# pse84_a0 register map
Vendor: Infineon Technologies; Series: PSE84_A0; File version: 1.0
CPU: CM33 r0p1, little endian, MPU, FPU, VTOR, 3 interrupt priority bits
Registers are 32-bit, read-write, reset 0x0 unless marked. A register's access mark holds for its fields unless they carry their own. Offsets are from the block's base; [hi:lo] are bit positions; lines under a group give offsets from that group; {n}, {i} and the like mark numbered series; 'fields as' and 'values as' point back to an identical list; <NAME> marks a mode.

## USBHS (part 4 of 7) — Regmap for both Subsystem and Controller IP
Base 0x44900000
0x00 DWC_OTG_INTREG group — Internal register map
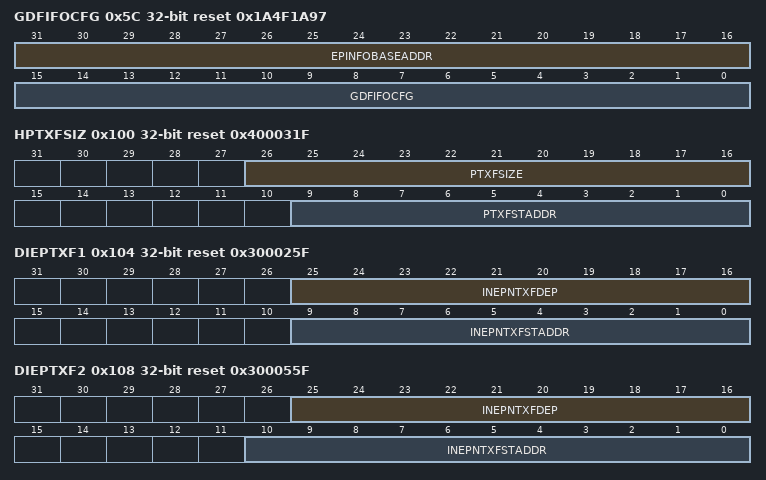
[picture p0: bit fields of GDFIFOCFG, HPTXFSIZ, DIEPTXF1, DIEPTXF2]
  0x5C GDFIFOCFG reset 0x1A4F1A97 — Register to configure the DFIFOs for the controller.
    [31:16] EPINFOBASEADDR — EPInfoBaseAddr This field provides the start address of the EP info controller.
    [15:0] GDFIFOCFG — GDFIFOCfg This field is for dynamic programming of the DFIFO Size. This value takes effect only when the application programs a non zero value to this register. The value programmed must conform to the guidelines described in 'FIFO RAM Allocation'. The core does not have any corrective logic if the FIFO sizes are programmed incorrectly.
  0x68 GINTMSK2 — This register works with the Interrupt Register (GINTSTS2) to interrupt the application. When an interrupt bit is masked, the interrupt associated with that bit is not generated. However, the GINTSTS2 register bit corresponding to that interrupt is still set. Note: The fields of this register change depending on host or device mode.
  0x6C GINTSTS2 — This register interrupts the application for system-level events in the current mode (Device mode or Host mode). Some of the bits in this register are valid only in Host mode, while others are valid in Device mode only. This register also indicates the current mode. To clear the interrupt status bits of type R_SS_WC, the application must write 1'b1 to the bit. The application must clear the GINTSTS2 register at initialization before unmasking the interrupt bit to avoid any interrupts generated prior to initialization.
  0x100 HPTXFSIZ reset 0x400031F — This register holds the size and the memory start address of the Periodic TxFIFO. Note: Read the reset value of this register only after the following conditions: - If IDDIG_FILTER is disabled, read only after PHY clock is stable. - If IDDIG_FILTER is enabled, read only after the filter timer expires.
    [26:16] PTXFSIZE — Host Periodic TxFIFO Depth (PTxFSize) This value is in terms of 32-bit words. - Minimum value is 16 - Maximum value is 32,768 The power-on reset value of this register is specified as the Largest Host Mode Periodic Tx Data FIFO Depth. - If Enable Dynamic FIFO Sizing? was deselected in coreConsultant (parameter OTG_DFIFO_DYNAMIC = 0), these flops are optimized, and reads return the power-on value. - If Enable Dynamic FIFO Sizing? was selected in coreConsultant (parameter OTG_DFIFO_DYNAMIC = 1), you can write a new value in this field. Programmed values must not exceed the power-on value set in coreConsultant.
    [9:0] PTXFSTADDR — Host Periodic TxFIFO Start Address (PTxFStAddr) The power-on reset value of this register is the sum of the Largest Rx Data FIFO Depth and Largest Non-periodic Tx Data FIFO Depth.These parameters are: In shared FIFO operation: - OTG_RX_DFIFO_DEPTH + OTG_TX_NPERIO_DFIFO_DEPTH In dedicated FIFO mode: - OTG_RX_DFIFO_DEPTH + OTG_TX_HNPERIO_DFIFO_DEPTH If Enable Dynamic FIFO Sizing? was deselected in coreConsultant (parameter OTG_DFIFO_DYNAMIC = 0), these flops are optimized, and reads return the power-on value. If Enable Dynamic FIFO Sizing? was selected in coreConsultant (parameter OTG_DFIFO_DYNAMIC = 1), you can write a new value in this field. Programmed values must not exceed the power-on value set in coreConsultant.
  0x104 DIEPTXF1 reset 0x300025F — This register is valid only in dedicated FIFO mode (OTG_EN_DED_TX_FIFO=1). It holds the size and memory start address of IN endpoint TxFIFOs implemented in Device mode. Each FIFO holds the data for one IN endpoint. This register is repeated for instantiated IN endpoint FIFOs 1 to 15. For IN endpoint FIFO 0, use GNPTXFSIZ register for programming the size and memory start address.
    [25:16] INEPNTXFDEP — IN Endpoint TxFIFO Depth (INEPnTxFDep) This value is in terms of 32-bit words. - Minimum value is 16 - Maximum value is 32,768 The power-on reset value of this register is specified as the Largest IN Endpoint FIFO number Depth (parameter OTG_TX_DINEP_DFIFO_DEPTH_n) during coreConsultant configuration (0 < i <= 15). - If 'Enable Dynamic FIFO Sizing?' was deselected in coreConsultant (parameter OTG_DFIFO_DYNAMIC = 0), these flops are optimized, and reads return the power-on value. - If 'Enable Dynamic FIFO Sizing?' was selected in coreConsultant (parameter OTG_DFIFO_DYNAMIC = 1), you can write a new value in this field. Programmed values must not exceed the power-on value.
    [9:0] INEPNTXFSTADDR — IN Endpoint FIFOn Transmit RAM Start Address (INEPnTxFStAddr) This field contains the memory start address for IN endpoint Transmit FIFOn (0<n< = 15). The power-on reset value of this register is specified as the Largest Rx Data FIFO Depth. The power-on reset value of this register is calculated according to the following formula: OTG_RX_DFIFO_DEPTH + SUM of OTG_TX_DINEP_DFIFO_DEPTH_'i' (where x = 0 to n 1) If at POR the calculated value (C) exceeds 65535, then the Reset value becomes Reset Value(A) = (C 65536). Example: If start address of IN endpoint FIFO 1 is OTG_RX_DFIFO_DEPTH + OTG_TX_DINEP_DFIFO_DEPTH_ 0 and start address of IN endpoint FIFO 2 is OTG_RX_DFIFO_DEPTH + OTG_TX_DINEP_DFIFO_DEPTH_ 0 + OTG_TX_DINEP_DFIFO_DEPTH_ 1. - If Enable Dynamic FIFO Sizing is deselected in coreConsultant (OTG_DFIFO_DYNAMIC = 0), this field is read-only and read value is the power-on reset value. - If Enable Dynamic FIFO Sizing is selected in coreConsultant (OTG_DFIFO_DYNAMIC = 1), and you have calculated or programmed a new value for RxFIFO depth or TX FIFO depths, you can program their values according to the above formula. Programmed values must not exceed the power-on value set in coreConsultant.
  0x108 DIEPTXF2 reset 0x300055F — This register is valid only in dedicated FIFO mode (OTG_EN_DED_TX_FIFO=1). It holds the size and memory start address of IN endpoint TxFIFOs implemented in Device mode. Each FIFO holds the data for one IN endpoint. This register is repeated for instantiated IN endpoint FIFOs 1 to 15. For IN endpoint FIFO 0, use GNPTXFSIZ register for programming the size and memory start address.
    [25:16] INEPNTXFDEP — IN Endpoint TxFIFO Depth (INEPnTxFDep) This value is in terms of 32-bit words. - Minimum value is 16 - Maximum value is 32,768 The power-on reset value of this register is specified as the Largest IN Endpoint FIFO number Depth (parameter OTG_TX_DINEP_DFIFO_DEPTH_n) during coreConsultant configuration (0 < i <= 15). - If 'Enable Dynamic FIFO Sizing?' was deselected in coreConsultant (parameter OTG_DFIFO_DYNAMIC = 0), these flops are optimized, and reads return the power-on value. - If 'Enable Dynamic FIFO Sizing?' was selected in coreConsultant (parameter OTG_DFIFO_DYNAMIC = 1), you can write a new value in this field. Programmed values must not exceed the power-on value.
    [10:0] INEPNTXFSTADDR — IN Endpoint FIFOn Transmit RAM Start Address (INEPnTxFStAddr) This field contains the memory start address for IN endpoint Transmit FIFOn (0<n< = 15). The power-on reset value of this register is specified as the Largest Rx Data FIFO Depth. The power-on reset value of this register is calculated according to the following formula: OTG_RX_DFIFO_DEPTH + SUM of OTG_TX_DINEP_DFIFO_DEPTH_'i' (where x = 0 to n 1) If at POR the calculated value (C) exceeds 65535, then the Reset value becomes Reset Value(A) = (C 65536). Example: If start address of IN endpoint FIFO 1 is OTG_RX_DFIFO_DEPTH + OTG_TX_DINEP_DFIFO_DEPTH_ 0 and start address of IN endpoint FIFO 2 is OTG_RX_DFIFO_DEPTH + OTG_TX_DINEP_DFIFO_DEPTH_ 0 + OTG_TX_DINEP_DFIFO_DEPTH_ 1. - If Enable Dynamic FIFO Sizing is deselected in coreConsultant (OTG_DFIFO_DYNAMIC = 0), this field is read-only and read value is the power-on reset value. - If Enable Dynamic FIFO Sizing is selected in coreConsultant (OTG_DFIFO_DYNAMIC = 1), and you have calculated or programmed a new value for RxFIFO depth or TX FIFO depths, you can program their values according to the above formula. Programmed values must not exceed the power-on value set in coreConsultant.
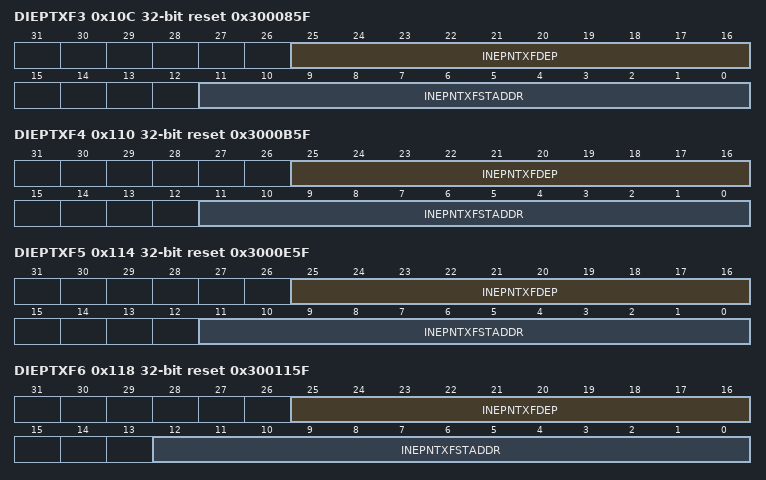
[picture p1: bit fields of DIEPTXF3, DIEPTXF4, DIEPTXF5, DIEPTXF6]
  0x10C DIEPTXF3 reset 0x300085F — This register is valid only in dedicated FIFO mode (OTG_EN_DED_TX_FIFO=1). It holds the size and memory start address of IN endpoint TxFIFOs implemented in Device mode. Each FIFO holds the data for one IN endpoint. This register is repeated for instantiated IN endpoint FIFOs 1 to 15. For IN endpoint FIFO 0, use GNPTXFSIZ register for programming the size and memory start address.
    [25:16] INEPNTXFDEP — IN Endpoint TxFIFO Depth (INEPnTxFDep) This value is in terms of 32-bit words. - Minimum value is 16 - Maximum value is 32,768 The power-on reset value of this register is specified as the Largest IN Endpoint FIFO number Depth (parameter OTG_TX_DINEP_DFIFO_DEPTH_n) during coreConsultant configuration (0 < i <= 15). - If 'Enable Dynamic FIFO Sizing?' was deselected in coreConsultant (parameter OTG_DFIFO_DYNAMIC = 0), these flops are optimized, and reads return the power-on value. - If 'Enable Dynamic FIFO Sizing?' was selected in coreConsultant (parameter OTG_DFIFO_DYNAMIC = 1), you can write a new value in this field. Programmed values must not exceed the power-on value.
    [11:0] INEPNTXFSTADDR — IN Endpoint FIFOn Transmit RAM Start Address (INEPnTxFStAddr) This field contains the memory start address for IN endpoint Transmit FIFOn (0<n< = 15). The power-on reset value of this register is specified as the Largest Rx Data FIFO Depth. The power-on reset value of this register is calculated according to the following formula: OTG_RX_DFIFO_DEPTH + SUM of OTG_TX_DINEP_DFIFO_DEPTH_'i' (where x = 0 to n 1) If at POR the calculated value (C) exceeds 65535, then the Reset value becomes Reset Value(A) = (C 65536). Example: If start address of IN endpoint FIFO 1 is OTG_RX_DFIFO_DEPTH + OTG_TX_DINEP_DFIFO_DEPTH_ 0 and start address of IN endpoint FIFO 2 is OTG_RX_DFIFO_DEPTH + OTG_TX_DINEP_DFIFO_DEPTH_ 0 + OTG_TX_DINEP_DFIFO_DEPTH_ 1. - If Enable Dynamic FIFO Sizing is deselected in coreConsultant (OTG_DFIFO_DYNAMIC = 0), this field is read-only and read value is the power-on reset value. - If Enable Dynamic FIFO Sizing is selected in coreConsultant (OTG_DFIFO_DYNAMIC = 1), and you have calculated or programmed a new value for RxFIFO depth or TX FIFO depths, you can program their values according to the above formula. Programmed values must not exceed the power-on value set in coreConsultant.
  0x110 DIEPTXF4 reset 0x3000B5F — This register is valid only in dedicated FIFO mode (OTG_EN_DED_TX_FIFO=1). It holds the size and memory start address of IN endpoint TxFIFOs implemented in Device mode. Each FIFO holds the data for one IN endpoint. This register is repeated for instantiated IN endpoint FIFOs 1 to 15. For IN endpoint FIFO 0, use GNPTXFSIZ register for programming the size and memory start address.
    fields as DWC_OTG_INTREG.DIEPTXF3
  0x114 DIEPTXF5 reset 0x3000E5F — This register is valid only in dedicated FIFO mode (OTG_EN_DED_TX_FIFO=1). It holds the size and memory start address of IN endpoint TxFIFOs implemented in Device mode. Each FIFO holds the data for one IN endpoint. This register is repeated for instantiated IN endpoint FIFOs 1 to 15. For IN endpoint FIFO 0, use GNPTXFSIZ register for programming the size and memory start address.
    fields as DWC_OTG_INTREG.DIEPTXF3
  0x118 DIEPTXF6 reset 0x300115F — This register is valid only in dedicated FIFO mode (OTG_EN_DED_TX_FIFO=1). It holds the size and memory start address of IN endpoint TxFIFOs implemented in Device mode. Each FIFO holds the data for one IN endpoint. This register is repeated for instantiated IN endpoint FIFOs 1 to 15. For IN endpoint FIFO 0, use GNPTXFSIZ register for programming the size and memory start address.
    [25:16] INEPNTXFDEP — IN Endpoint TxFIFO Depth (INEPnTxFDep) This value is in terms of 32-bit words. - Minimum value is 16 - Maximum value is 32,768 The power-on reset value of this register is specified as the Largest IN Endpoint FIFO number Depth (parameter OTG_TX_DINEP_DFIFO_DEPTH_n) during coreConsultant configuration (0 < i <= 15). - If 'Enable Dynamic FIFO Sizing?' was deselected in coreConsultant (parameter OTG_DFIFO_DYNAMIC = 0), these flops are optimized, and reads return the power-on value. - If 'Enable Dynamic FIFO Sizing?' was selected in coreConsultant (parameter OTG_DFIFO_DYNAMIC = 1), you can write a new value in this field. Programmed values must not exceed the power-on value.
    [12:0] INEPNTXFSTADDR — IN Endpoint FIFOn Transmit RAM Start Address (INEPnTxFStAddr) This field contains the memory start address for IN endpoint Transmit FIFOn (0<n< = 15). The power-on reset value of this register is specified as the Largest Rx Data FIFO Depth. The power-on reset value of this register is calculated according to the following formula: OTG_RX_DFIFO_DEPTH + SUM of OTG_TX_DINEP_DFIFO_DEPTH_'i' (where x = 0 to n 1) If at POR the calculated value (C) exceeds 65535, then the Reset value becomes Reset Value(A) = (C 65536). Example: If start address of IN endpoint FIFO 1 is OTG_RX_DFIFO_DEPTH + OTG_TX_DINEP_DFIFO_DEPTH_ 0 and start address of IN endpoint FIFO 2 is OTG_RX_DFIFO_DEPTH + OTG_TX_DINEP_DFIFO_DEPTH_ 0 + OTG_TX_DINEP_DFIFO_DEPTH_ 1. - If Enable Dynamic FIFO Sizing is deselected in coreConsultant (OTG_DFIFO_DYNAMIC = 0), this field is read-only and read value is the power-on reset value. - If Enable Dynamic FIFO Sizing is selected in coreConsultant (OTG_DFIFO_DYNAMIC = 1), and you have calculated or programmed a new value for RxFIFO depth or TX FIFO depths, you can program their values according to the above formula. Programmed values must not exceed the power-on value set in coreConsultant.
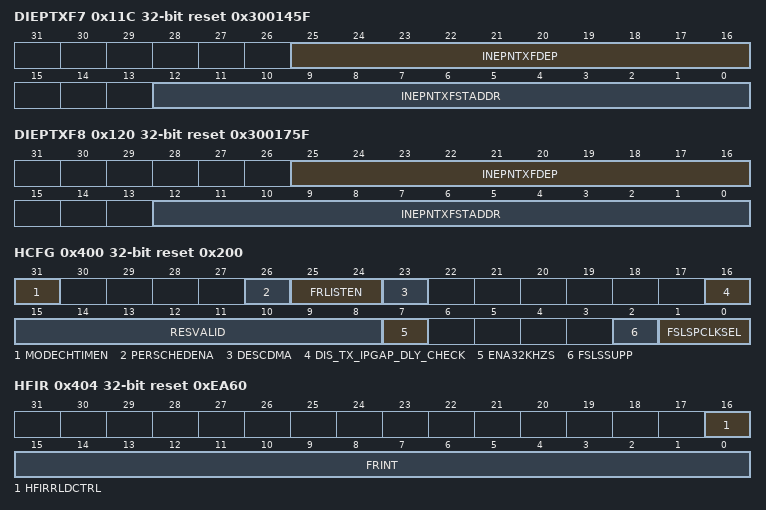
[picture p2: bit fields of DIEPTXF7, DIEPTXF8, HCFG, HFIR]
  0x11C DIEPTXF7 reset 0x300145F — This register is valid only in dedicated FIFO mode (OTG_EN_DED_TX_FIFO=1). It holds the size and memory start address of IN endpoint TxFIFOs implemented in Device mode. Each FIFO holds the data for one IN endpoint. This register is repeated for instantiated IN endpoint FIFOs 1 to 15. For IN endpoint FIFO 0, use GNPTXFSIZ register for programming the size and memory start address.
    fields as DWC_OTG_INTREG.DIEPTXF6
  0x120 DIEPTXF8 reset 0x300175F — This register is valid only in dedicated FIFO mode (OTG_EN_DED_TX_FIFO=1). It holds the size and memory start address of IN endpoint TxFIFOs implemented in Device mode. Each FIFO holds the data for one IN endpoint. This register is repeated for instantiated IN endpoint FIFOs 1 to 15. For IN endpoint FIFO 0, use GNPTXFSIZ register for programming the size and memory start address.
    fields as DWC_OTG_INTREG.DIEPTXF6
  0x400 HCFG reset 0x200 — This register is used to configure the controller in Host mode.
    [31] MODECHTIMEN — Mode Change Ready Timer Enable (ModeChTimEn) This bit is used to enable/disable the Host core to wait 200 PHY clock cycles at the end of Resume to change the opmode signal to the PHY to 00 after Suspend or LPM. - 1'b0 : The Host core waits for either 200 PHY clock cycles or a linestate of SE0 at the end of resume to the change the opmode from 2'b10 to 2'b00 - 1'b1 : The Host core waits only for a linstate of SE0 at the end of resume to change the opmode from 2'b10 to 2'b00.
      1=DISABLED (The Host core waits only for a linestate of SE0 at the end of resume to change the opmode from 0x2 to 0x0); 0=ENABLED (The Host core waits for either 200 PHY clock cycles or a linestate of SE0 at the end of resume to change the opmode from 0x2 to 0x0)
    [26] PERSCHEDENA — Enable Periodic Scheduling (PerSchedEna): Applicable in host DDMA mode only. Enables periodic scheduling within the core. Initially, the bit is reset. The core will not process any periodic channels. As soon as this bit is set, the core will get ready to start scheduling periodic channels and sets HCFG.PerSchedStat. The setting of HCFG.PerSchedStat indicates the core has enabled periodic scheduling. Once HCFG.PerSchedEna is set, the application is not supposed to again reset the bit unless HCFG.PerSchedStat is set. As soon as this bit is reset, the core will get ready to stop scheduling periodic channels and resets HCFG.PerSchedStat.
      0=DISABLED (Disables periodic scheduling within the core); 1=ENABLED (Enables periodic scheduling within the core)
    [25:24] FRLISTEN — Frame List Entries(FrListEn) The value in the register specifies the number of entries in the Frame list. This field is valid only in Scatter/Gather DMA mode. - 2'b00: 8 Entries - 2'b01: 16 Entries - 2'b10: 32 Entries - 2'b11: 64 Entries
      1=ENTRY16 (16 Entries); 2=ENTRY32 (32 Entries); 3=ENTRY63 (64 Entries); 0=ENTRY8 (8 Entries)
    [23] DESCDMA — Enable Scatter/gather DMA in Host mode (DescDMA) When the Scatter/Gather DMA option selected during configuration of the RTL, the application can set this bit during initialization to enable the Scatter/Gather DMA operation. Note: This bit must be modified only once after a reset. The following combinations are available for programming: - GAHBCFG.DMAEn=0,HCFG.DescDMA=0 => Slave mode - GAHBCFG.DMAEn=0,HCFG.DescDMA=1 => Invalid - GAHBCFG.DMAEn=1,HCFG.DescDMA=0 => Buffered DMA mode - GAHBCFG.DMAEn=1,HCFG.DescDMA=1 => Scatter/Gather DMA mode
      0=DISABLED (Scatter/Gather DMA in Host mode is disabled); 1=ENABLED (Scatter/Gather DMA selected)
    [16] DIS_TX_IPGAP_DLY_CHECK — Disable Linestate check for Token to Token/Data interpacket gap delay calculation (dis_tx_ipgap_dly_check) Applicable only in HS mode of operation. When enabled, the controller implements counter based logic to detect the end of token transmission, otherwise controller monitors the linestate for end of token transmission,to start the Token to Token and Token to Data interpacket delay counter.
      0=DISABLE (Enable Linestate check); 1=ENABLE (Disable Linestate check)
    [15:8] RESVALID — Resume Validation Period (ResValid) This field is effective only when HCFG.Ena32KHzS is set. It will control the resume period when the core resumes from suspend. The core counts for 'ResValid' number of clock cycles to detect a valid resume when this is set.
    [7] ENA32KHZS — Enable 32 KHz Suspend mode (Ena32KHzS) This bit can be set only in FS PHY interface is selected. Else, this bit needs to be set to zero. When FS PHY interface is chosen and this bit is set, the core expects that the PHY clock during Suspend is switched from 48 MHz to 32 KHz.
      0=DISABLED (32 KHz Suspend mode disabled); 1=ENABLED (32 KHz Suspend mode enabled)
    [2] FSLSSUPP — FS- and LS-Only Support (FSLSSupp) The application uses this bit to control the core's enumeration speed. Using this bit, the application can make the core enumerate as a FS host, even If the connected device supports HS traffic. Do not make changes to this field after initial programming. - 1'b0: HS/FS/LS, based on the maximum speed supported by the connected device - 1'b1: FS/LS-only, even If the connected device can support HS
      1=FSLS (FS/LS-only, even if the connected device can support HS); 0=HSFSLS (HS/FS/LS, based on the maximum speed supported by the connected device)
    [1:0] FSLSPCLKSEL
      0=CLK3060 (PHY clock is running at 30/60 MHz); 1=CLK48 (PHY clock is running at 48 MHz); 2=CLK6 (PHY clock is running at 6 MHz)
  0x404 HFIR reset 0xEA60 — This register is used to control the interval between two consecutive SOFs.
    [16] HFIRRLDCTRL — Reload Control (HFIRRldCtrl) This bit allows dynamic reloading of the HFIR register during run time. - 1'b0 : The HFIR cannot be reloaded dynamically - 1'b1: the HFIR can be dynamically reloaded during runtime. This bit needs to be programmed during initial configuration and its value should not be changed during runtime.
      0=DISABLED (The HFIR cannot be reloaded dynamically); 1=ENABLED (The HFIR can be dynamically reloaded during runtime)
    [15:0] FRINT — Frame Interval (FrInt) The value that the application programs to this field specifies the interval between two consecutive SOFs (FS) or micro- SOFs (HS) or Keep-Alive tokens (HS). This field contains the number of PHY clocks that constitute the required frame interval. The Default value set in this field is for FS operation when the PHY clock frequency is 60 MHz. The application can write a value to this register only after the Port Enable bit of the Host Port Control and Status register (HPRT.PrtEnaPort) has been Set. If no value is programmed, the core calculates the value based on the PHY clock specified in the FS/LS PHY Clock Select field of the Host Configuration register (HCFG.FSLSPclkSel). Do not change the value of this field after the initial configuration. - 125 s * (PHY clock frequency for HS) - 1 ms * (PHY clock frequency for FS/LS)
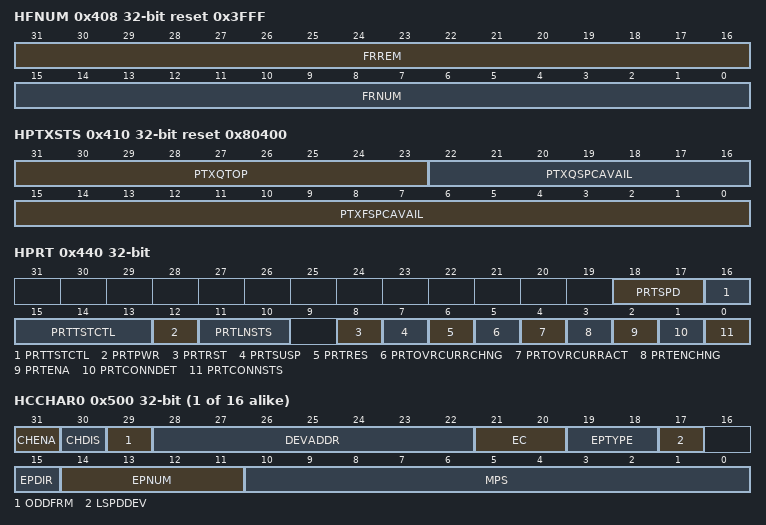
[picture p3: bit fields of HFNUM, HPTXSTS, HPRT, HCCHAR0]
  0x408 HFNUM ro reset 0x3FFF — This register indicates the current frame number. It also indicates the time remaining (in terms of the number of PHY clocks) in the current (micro)frame. Note: Read the reset value of this register only after the following conditions: - If IDDIG_FILTER is disabled, read only when the PHY clock is stable. - If IDDIG_FILTER is enabled, read only after the filter timer expires.
    [31:16] FRREM — Frame Time Remaining (FrRem) Indicates the amount of time remaining in the current microframe (HS) or Frame (FS/LS), in terms of PHY clocks. This field decrements on each PHY clock. When it reaches zero, this field is reloaded with the value in the Frame Interval register and a new SOF is transmitted on the USB.
    [15:0] FRNUM — Frame Number (FrNum) This field increments when a new SOF is transmitted on the USB, and is reset to 0 when it reaches 16'h3FFF.
  0x410 HPTXSTS ro reset 0x80400 — This register contains information about the Periodic Transmit Queue in the Host controller.
    [31:23] PTXQTOP — Top of the Periodic Transmit Request Queue (PTxQTop) This indicates the Entry in the Periodic Tx Request Queue that is currently being processed by the MAC. This register is used for debugging. - Bit [31]: Odd/Even (micro)Frame -- 1'b0: send in even (micro)Frame -- 1'b1: send in odd (micro)Frame - Bits [30:27]: Channel/endpoint number - Bits [26:25]: Type -- 2'b00: IN/OUT -- 2'b01: Zero-length packet -- 2'b10: CSPLIT -- 2'b11: Disable channel command - Bit [24]: Last Periodic Entry for the selected periodic channel/endpoint - Bit [23]: Terminate (last Entry for the selected channel/endpoint)
    [22:16] PTXQSPCAVAIL
    [15:0] PTXFSPCAVAIL
  0x414 HAINT ro — When a significant event occurs on a channel, the Host All Channels Interrupt register interrupts the application using the Host Channels Interrupt bit of the Core Interrupt register (GINTSTS.HChInt). This is shown in the 'Interrupt Hierarchy' figure in the databook. There is one interrupt bit per channel, up to a maximum of 16 bits. Bits in this register are set and cleared when the application sets and clears bits in the corresponding Host Channel-n Interrupt register.
    [15:0] HAINT — Channel Interrupt for channel no.
  0x418 HAINTMSK — The Host All Channel Interrupt Mask register works with the Host All Channel Interrupt register to interrupt the application when an event occurs on a channel. There is one interrupt mask bit per channel, up to a maximum of 16 bits.
    [15:0] HAINTMSK — Channel Interrupt Mask (HAINTMsk) One bit per channel: Bit 0 for channel 0, bit 15 for channel 15
  0x41C HFLBADDR — This register is present only in case of Scatter/Gather DMA. It is implemented as flops. This register holds the starting address of the Frame list information.
    [31:0] HFLBADDR — The starting address of the Frame list. This register is used only for Isochronous and Interrupt Channels.
  0x440 HPRT — This register is available only in Host mode. Currently, the OTG Host supports only one port. A single register holds USB port-related information such as USB reset, enable, suspend, resume, connect status, and test mode for each port. It is shown in the 'Interrupt Hierarchy' figure in the databook. The R_SS_WC bits in this register can trigger an interrupt to the application through the Host Port Interrupt bit of the Core Interrupt register (GINTSTS.PrtInt). On a Port Interrupt, the application must read this register and clear the bit that caused the interrupt. For the R_SS_WC bits, the application must write a 1 to the bit to clear the interrupt.
    [18:17] PRTSPD ro
      1=FULLSPD (Full speed); 0=HIGHSPD (High speed); 2=LOWSPD (Low speed); 3=RSVDPrtSpdHPRT (N/A)
    [16:13] PRTTSTCTL
      0=DISABLED (Test mode disabled); 5=TESTFENB (Test_force_Enable); 1=TESTJ (Test_J mode); 2=TESTK (Test_K mode); 4=TESTPM (Test_Packet mode); 3=TESTSN (Test_SE0_NAK mode)
    [12] PRTPWR — Port Power (PrtPwr) The application uses this field to control power to this port (write 1'b1 to set to 1'b1 and write 1'b0 to set to 1'b0), and the core can clear this bit on an over current condition. - 1'b0: Power off - 1'b1: Power on Note: This bit is interface independent. The application needs to program this bit for all interfaces as described in the host programming flow in the Programming Guide.
      0=OFF (Power off); 1=ON (Power on)
    [11:10] PRTLNSTS ro — Port Line Status (PrtLnSts) Indicates the current logic level USB data lines - Bit [10]: Logic level of D+ - Bit [11]: Logic level of D-
      2=MINUSD (Logic level of D-); 1=PLUSD (Logic level of D+)
    [8] PRTRST — Port Reset (PrtRst) When the application sets this bit, a reset sequence is started on this port. The application must time the reset period and clear this bit after the reset sequence is complete. - 1'b0: Port not in reset - 1'b1: Port in reset The application must leave this bit set for at least a minimum duration mentioned below to start a reset on the port. The application can leave it set for another 10 ms in addition to the required minimum duration, before clearing the bit, even though there is no maximum limit Set by the USB standard.This bit is cleared by the core even if there is no device connected to the Host. - High speed: 50 ms - Full speed/Low speed: 10 ms
      0=DISABLED (Port not in reset); 1=ENABLED (Port in reset)
    [7] PRTSUSP — Port Suspend (PrtSusp) The application sets this bit to put this port in Suspend mode. The core only stops sending SOFs when this is Set. To stop the PHY clock, the application must Set the Port Clock Stop bit, which asserts the suspend input pin of the PHY. The read value of this bit reflects the current suspend status of the port. This bit is cleared by the core after a remote wakeup signal is detected or the application sets the Port Reset bit or Port Resume bit in this register or the Resume/Remote Wakeup Detected Interrupt bit or Disconnect Detected Interrupt bit in the Core Interrupt register (GINTSTS.WkUpInt or GINTSTS.DisconnInt, respectively).This bit is cleared by the core even if there is no device connected to the Host. - 1'b0: Port not in Suspend mode - 1'b1: Port in Suspend mode
      1=ACTIVE (Port in Suspend mode); 0=INACTIVE (Port not in Suspend mode)
    [6] PRTRES — Port Resume (PrtRes) The application sets this bit to drive resume signaling on the port. The core continues to drive the resume signal until the application clears this bit. If the core detects a USB remote wakeup sequence, as indicated by the Port Resume/Remote Wakeup Detected Interrupt bit of the Core Interrupt register (GINTSTS.WkUpInt), the core starts driving resume signaling without application intervention and clears this bit when it detects a disconnect condition. The read value of this bit indicates whether the core is currently driving resume signaling. - 1'b0: No resume driven - 1'b1: Resume driven When LPM is enabled, In L1 state the behavior of this bit is as follows: The application sets this bit to drive resume signaling on the port. The core continues to drive the resume signal until a pre-determined time specified in GLPMCFG.HIRD_Thres[3:0] field. If the core detects a USB remote wakeup sequence, as indicated by the Port L1Resume/Remote L1Wakeup Detected Interrupt bit of the Core Interrupt register (GINTSTS.L1WkUpInt), the core starts driving resume signaling without application intervention and clears this bit at the end of resume.This bit can be set by both core or application and also cleared by core or application. This bit is cleared by the core even if there is no device connected to the Host.
      0=NORESUME (No resume driven); 1=RESUME (Resume driven)
    [5] PRTOVRCURRCHNG — Port Overcurrent Change (PrtOvrCurrChng) The core sets this bit when the status of the Port Overcurrent Active bit (bit 4) in this register changes.This bit can be set only by the core and the application should write 1 to clear it
      1=ACTIVE (Status of port overcurrent changed); 0=INACTIVE (Status of port overcurrent status is not changed)
    [4] PRTOVRCURRACT ro — Port Overcurrent Active (PrtOvrCurrAct) Indicates the overcurrent condition of the port. - 1'b0: No overcurrent condition - 1'b1: Overcurrent condition
      1=ACTIVE (Overcurrent condition); 0=INACTIVE (No overcurrent condition)
    [3] PRTENCHNG — Port Enable/Disable Change (PrtEnChng) The core sets this bit when the status of the Port Enable bit [2] of this register changes.This bit can be set only by the core and the application should write 1 to clear it.
      1=ACTIVE (Port Enable bit 2 changed); 0=INACTIVE (Port Enable bit 2 has not changed)
    [2] PRTENA — Port Enable (PrtEna) A port is enabled only by the core after a reset sequence, and is disabled by an overcurrent condition, a disconnect condition, or by the application clearing this bit. The application cannot Set this bit by a register write. It can only clear it to disable the port by writing 1. This bit does not trigger any interrupt to the application. - 1'b0: Port disabled - 1'b1: Port enabled
      0=DISABLED (Port disabled); 1=ENABLED (Port enabled)
    [1] PRTCONNDET — Port Connect Detected (PrtConnDet) The core sets this bit when a device connection is detected to trigger an interrupt to the application using the Host Port Interrupt bit of the Core Interrupt register (GINTSTS.PrtInt).This bit can be set only by the core and the application should write 1 to clear it.The application must write a 1 to this bit to clear the interrupt.
      1=ACTIVE (Device connection detected); 0=INACTIVE (No device connection detected)
    [0] PRTCONNSTS ro — Port Connect Status (PrtConnSts) - 0: No device is attached to the port. - 1: A device is attached to the port.
      1=ATTACHED (A device is attached to the port); 0=NOTATTACHED (No device is attached to the port)
  {0x500+0x20*j} HCCHAR{j} (j=0..15) — This register contains the characteristics of the Host Channel.
    [31] CHENA — Channel Enable (ChEna) When Scatter/Gather mode is enabled - 1'b0: Indicates that the descriptor structure is not yet ready. - 1'b1: Indicates that the descriptor structure and data buffer with data is setup and this channel can access the descriptor. When Scatter/Gather mode is disabled This field is set by the application and cleared by the OTG host. - 1'b0: Channel disabled - 1'b1: Channel enabled
      0=DISABLED (If Scatter/Gather mode is enabled, indicates that the descriptor structure is not yet ready. If Scatter/Gather mode is disabled, indicates that the channel is disabled.); 1=ENABLED (If Scatter/Gather mode is enabled, indicates that the descriptor structure and data buffer with data is set up and this channel can access the descriptor. If Scatter/Gather mode is disabled, indicates that the channel is enabled.)
    [30] CHDIS — Channel Disable (ChDis) The application sets this bit to stop transmitting/receiving data on a channel, even before the transfer for that channel is complete. The application must wait for the Channel Disabled interrupt before treating the channel as disabled.
      1=ACTIVE (Stop transmitting/receiving data on channel); 0=INACTIVE (Transmit/Recieve normal)
    [29] ODDFRM — Odd Frame (OddFrm) This field is set (reset) by the application to indicate that the OTG host must perform a transfer in an odd (micro)Frame. This field is applicable for only periodic (isochronous and interrupt) transactions. - 1'b0: Even (micro)Frame - 1'b1: Odd (micro)Frame
      0=EFRAME (Even Frame Transfer); 1=OFRAME (Odd Frame Transfer)
    [28:22] DEVADDR — Device Address (DevAddr) This field selects the specific device serving as the data source or sink.
    [21:20] EC
      0=RSVDECHCCHAR{j} (N/A); 1=TRANSONE (1 transaction); 3=TRANSTHREE (3 transactions to be issued for this endpoint per microframe); 2=TRANSTWO (2 transactions to be issued for this endpoint per microframe)
    [19:18] EPTYPE — Endpoint Type (EPType) Indicates the transfer type selected. - 2'b00: Control - 2'b01: Isochronous - 2'b10: Bulk - 2'b11: Interrupt
      2=BULK; 0=CTRL (Control); 3=INTERR (Interrupt); 1=ISOC (Isochronous)
    [17] LSPDDEV — Low-Speed Device (LSpdDev) This field is Set by the application to indicate that this channel is communicating to a low-speed device. The application must program this bit when a low speed device is connected to the host through an FS HUB. The DWC_otg Host core uses this field to drive the XCVR_SELECT signal to 2'b11 while communicating to the LS Device through the FS hub. Note: In a peer to peer setup, the DWC_otg Host core ignores this bit even if it is set by the application software.
      0=DISABLED (Not Communicating with low speed device); 1=ENABLED (Communicating with low speed device)
    [15] EPDIR — Endpoint Direction (EPDir) Indicates whether the transaction is IN or OUT. - 1'b0: OUT - 1'b1: IN
      1=IN (IN Direction); 0=OUT (OUT Direction)
    [14:11] EPNUM — Endpoint Number (EPNum) Indicates the endpoint number on the device serving as the data source or sink.
      {v}=ENDPT{v} (End point {v}) (v=0..15)
    [10:0] MPS — Maximum Packet Size (MPS) Indicates the maximum packet size of the associated endpoint.
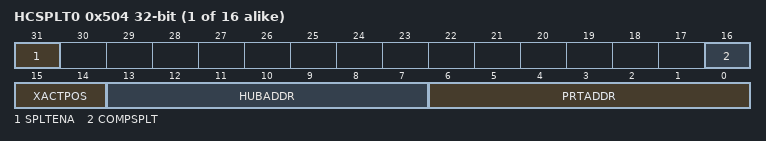
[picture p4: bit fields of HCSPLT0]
  {0x504+0x20*j} HCSPLT{j} (j=0..15) — This register contains the Split characteristics of the Host Channel.
    [31] SPLTENA — Split Enable (SpltEna) The application sets this field to indicate that this channel is enabled to perform split transactions.
      0=DISABLED (Split not enabled); 1=ENABLED (Split enabled)
    [16] COMPSPLT — Do Complete Split (CompSplt) The application sets this field to request the OTG host to perform a complete split transaction.
      0=NOSPLIT (No complete split transaction); 1=SPLIT (Complete Split transaction)
    [15:14] XACTPOS — Transaction Position (XactPos) This field is used to determine whether to send all, first, middle, or last payloads with each OUT transaction. - 2'b11: All. This is the entire data payload is of this transaction (which is less than or equal to 188 bytes). - 2'b10: Begin. This is the first data payload of this transaction (which is larger than 188 bytes). - 2'b00: Mid. This is the middle payload of this transaction (which is larger than 188 bytes). - 2'b01: End. This is the last payload of this transaction (which is larger than 188 bytes).
      3=ALL (All. This is the entire data payload of this transaction (which is less than or equal to 188 bytes)); 2=BEGIN (Begin. This is the first data payload of this transaction (which is larger than 188 bytes)); 1=END (End. This is the last payload of this transaction (which is larger than 188 bytes)); 0=MIDDLE (Mid. This is the middle payload of this transaction (which is larger than 188 bytes))
    [13:7] HUBADDR — Hub Address (HubAddr) This field holds the device address of the transaction translator's hub.
    [6:0] PRTADDR — Port Address (PrtAddr) This field is the port number of the recipient transaction translator.
